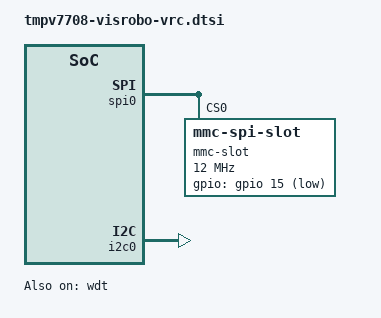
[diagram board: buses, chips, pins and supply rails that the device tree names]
// SPDX-License-Identifier: (GPL-2.0+ OR MIT)
/*
 * Device Tree File for TMPV7708 VisROBO VRC SoM
 *
 * (C) Copyright 2020, 2021, Toshiba Corporation.
 * (C) Copyright 2020, Nobuhiro Iwamatsu <nobuhiro1.iwamatsu@toshiba.co.jp>
 */

/dts-v1/;

#include "tmpv7708.dtsi"
#include <dt-bindings/gpio/gpio.h>

&wdt {
	status = "okay";
};

&gpio {
	status = "okay";
};

&spi0_pins {
	groups = "spi0_grp", "spi0_cs0_grp";
};

&spi0 {
	status = "okay";

	mmc-slot@0 {
		compatible = "mmc-spi-slot";
		reg = <0>;
		gpios = <&gpio 15 GPIO_ACTIVE_LOW>;
		voltage-ranges = <3200 3400>;
		spi-max-frequency = <12000000>;
	};
};

&i2c0 {
	status = "okay";
};
